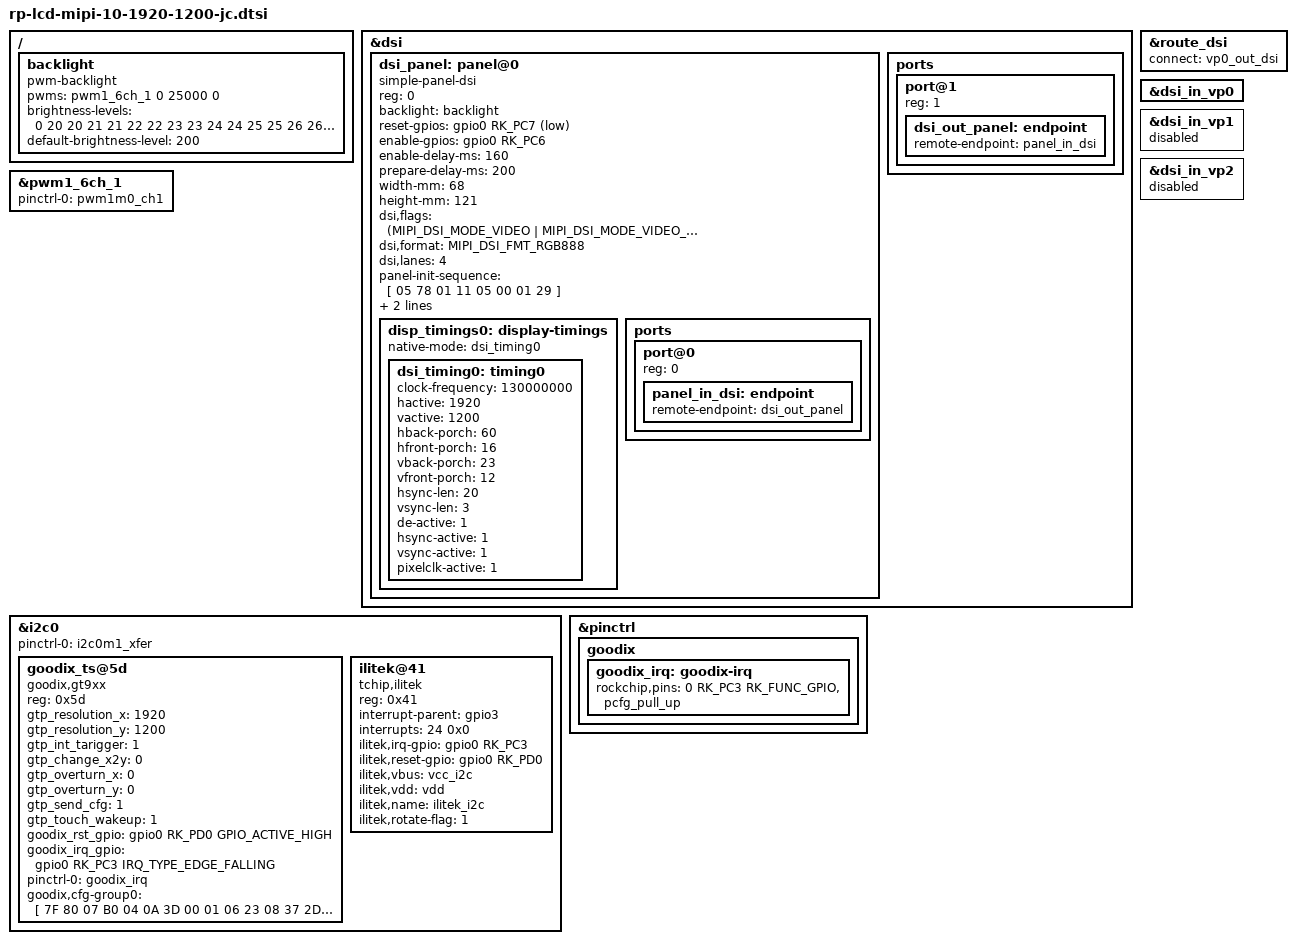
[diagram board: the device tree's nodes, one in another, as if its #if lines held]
/{
    backlight: backlight {
        compatible = "pwm-backlight";
        pwms = <&pwm1_6ch_1 0 25000 0>;
        brightness-levels = <
              0  20  20  21  21  22  22  23
             23  24  24  25  25  26  26  27
             27  28  28  29  29  30  30  31
             31  32  32  33  33  34  34  35
             35  36  36  37  37  38  38  39
             40  41  42  43  44  45  46  47
             48  49  50  51  52  53  54  55
             56  57  58  59  60  61  62  63
             64  65  66  67  68  69  70  71
             72  73  74  75  76  77  78  79
             80  81  82  83  84  85  86  87
             88  89  90  91  92  93  94  95
             96  97  98  99 100 101 102 103
            104 105 106 107 108 109 110 111
            112 113 114 115 116 117 118 119
            120 121 122 123 124 125 126 127
            128 129 130 131 132 133 134 135
            136 137 138 139 140 141 142 143
            144 145 146 147 148 149 150 151
            152 153 154 155 156 157 158 159
            160 161 162 163 164 165 166 167
            168 169 170 171 172 173 174 175
            176 177 178 179 180 181 182 183
            184 185 186 187 188 189 190 191
            192 193 194 195 196 197 198 199
            200 201 202 203 204 205 206 207
            208 209 210 211 212 213 214 215
            216 217 218 219 220 221 222 223
            224 225 226 227 228 229 230 231
            232 233 234 235 236 237 238 239
            240 241 242 243 244 245 246 247
            248 249 250 251 252 253 254 255
        >;
        default-brightness-level = <200>;
    };
};


&dsi {
    status = "okay";
   // rockchip,lane-rate = <1200>;
    dsi_panel: panel@0 {
        status = "okay";
        compatible = "simple-panel-dsi";
        reg = <0>;
        backlight = <&backlight>;
        
        reset-gpios = <&gpio0 RK_PC7 GPIO_ACTIVE_LOW>;
        enable-gpios = <&gpio0 RK_PC6 GPIO_ACTIVE_HIGH>;
       
	 //    reset-delay-ms = <60>;
    //    init-delay-ms = <60>;
        enable-delay-ms = <160>;
        prepare-delay-ms = <200>;
    //    unprepare-delay-ms = <60>;
    //    disable-delay-ms = <60>;

 
        width-mm = <68>;
        height-mm = <121>;
        dsi,flags = <(MIPI_DSI_MODE_VIDEO | MIPI_DSI_MODE_VIDEO_BURST |
                  MIPI_DSI_MODE_LPM | MIPI_DSI_MODE_NO_EOT_PACKET)>;
        dsi,format = <MIPI_DSI_FMT_RGB888>;
        dsi,lanes  = <4>;
        panel-init-sequence = [
            05 78 01 11
            05 00 01 29
        ];

        panel-exit-sequence = [
            05 00 01 28
            05 00 01 10
        ];

        disp_timings0: display-timings {
            native-mode = <&dsi_timing0>;
            dsi_timing0: timing0 {
		clock-frequency = <130000000>;
                                hactive = <1920>;
                                vactive = <1200>;
                                hback-porch = <60>;    //60
                                hfront-porch = <16>;    //16
                                vback-porch = <23>;    //23
                                vfront-porch = <12>;    //12
                                hsync-len = <20>;    //20
                                vsync-len = <3>;    //3
                                de-active = <1>;
                                hsync-active = <1>;
                                vsync-active = <1>;
                                pixelclk-active = <1>;

            };
        };

        ports {
            #address-cells = <1>;
            #size-cells = <0>;

            port@0 {
                reg = <0>;
                panel_in_dsi: endpoint {
                    remote-endpoint = <&dsi_out_panel>;
                };
            };
        };
    };

    ports {
        #address-cells = <1>;
        #size-cells = <0>;

        port@1 {
            reg = <1>;
            dsi_out_panel: endpoint {
                remote-endpoint = <&panel_in_dsi>;
            };
        };
    };

};


#if defined RP_RK3576S || defined DR4_RK3576X || defined PRO_RK3576X

&route_dsi {
    status = "okay";
    connect = <&vp0_out_dsi>;
};

&pwm1_6ch_1 {
    status = "okay";
    pinctrl-0 = <&pwm1m0_ch1>;
};

&dsi_in_vp0 {
    status = "okay";
};

&dsi_in_vp1 {
    status = "disabled";
};

&dsi_in_vp2 {
    status = "disabled";
};


#else  //rk3576

&route_dsi {
    status = "okay";
};

&pwm1_6ch_1 {
    status = "okay";
    pinctrl-0 = <&pwm1m0_ch1>;
};

//default to hdmi
&dsi_in_vp0 {
    status = "disabled";
};

&dsi_in_vp1 {
    status = "okay";
};

&dsi_in_vp2 {
    status = "disabled";
};

&dsi_in_vopl {
    status = "okay";
};
#endif
 

//TP
&i2c0 {
    status = "okay";
    pinctrl-names = "default";
    pinctrl-0 = <&i2c0m1_xfer>;
    goodix_ts@5d {
        compatible = "goodix,gt9xx";
        reg = <0x5d>;
        gtp_resolution_x = <1920>;
        gtp_resolution_y = <1200>;
        gtp_int_tarigger = <1>;
        gtp_change_x2y = <0>;
        gtp_overturn_x = <0>;
        gtp_overturn_y = <0>;
        gtp_send_cfg = <1>;
        gtp_touch_wakeup = <1>;
        goodix_rst_gpio = <&gpio0 RK_PD0 GPIO_ACTIVE_HIGH>;
        goodix_irq_gpio = <&gpio0 RK_PC3 IRQ_TYPE_EDGE_FALLING>;
	pinctrl-names = "default";
        pinctrl-0 = <&goodix_irq>;
        goodix,cfg-group0 = [
                7F 80 07 B0 04 0A 3D 00 01 06 23
                08 37 2D 03 05 00 00 00 00 00 00
                04 17 19 1D 14 90 30 AA 53 55 0C
                08 00 00 00 01 03 1D 00 00 00 00
                00 00 00 00 00 00 00 3C 78 94 D0
                42 00 08 00 04 8E 40 00 85 4A 00
                7F 55 00 7B 61 00 7A 70 00 7B 00
                00 00 00 00 00 00 00 00 00 00 00
                00 00 00 00 00 00 00 00 00 00 00
                00 00 00 00 00 00 00 00 00 00 00
                00 00 19 18 17 16 15 14 11 10 0F
                0E 0D 0C 09 08 07 06 05 04 01 00
                00 00 00 00 00 00 00 00 00 00 19
                1B 1C 1E 1F 20 21 22 23 24 25 26
                27 28 29 2A 14 13 12 11 10 0F 0E
                0D 0C 0A 08 07 06 04 02 00 00 00
                00 00 00 00 00 00 00 00 BE 01   
            ];
    };
        ilitek@41 {
	        compatible = "tchip,ilitek";
	        reg = <0x41>;
	        interrupt-parent = <&gpio3>;
	        interrupts = <24 0x0>;
	        ilitek,irq-gpio = <&gpio0 RK_PC3 IRQ_TYPE_EDGE_FALLING>;
	        ilitek,reset-gpio = <&gpio0 RK_PD0 GPIO_ACTIVE_HIGH>;
	        ilitek,vbus = "vcc_i2c";
	        ilitek,vdd = "vdd";
	        ilitek,name = "ilitek_i2c";
            ilitek,rotate-flag = <1>; //1 or 0; 1 is swap x2y;
        };
};

&pinctrl {
    goodix {
        goodix_irq: goodix-irq {
            rockchip,pins = <0 RK_PC3 RK_FUNC_GPIO &pcfg_pull_up>;
        };
    };
};


